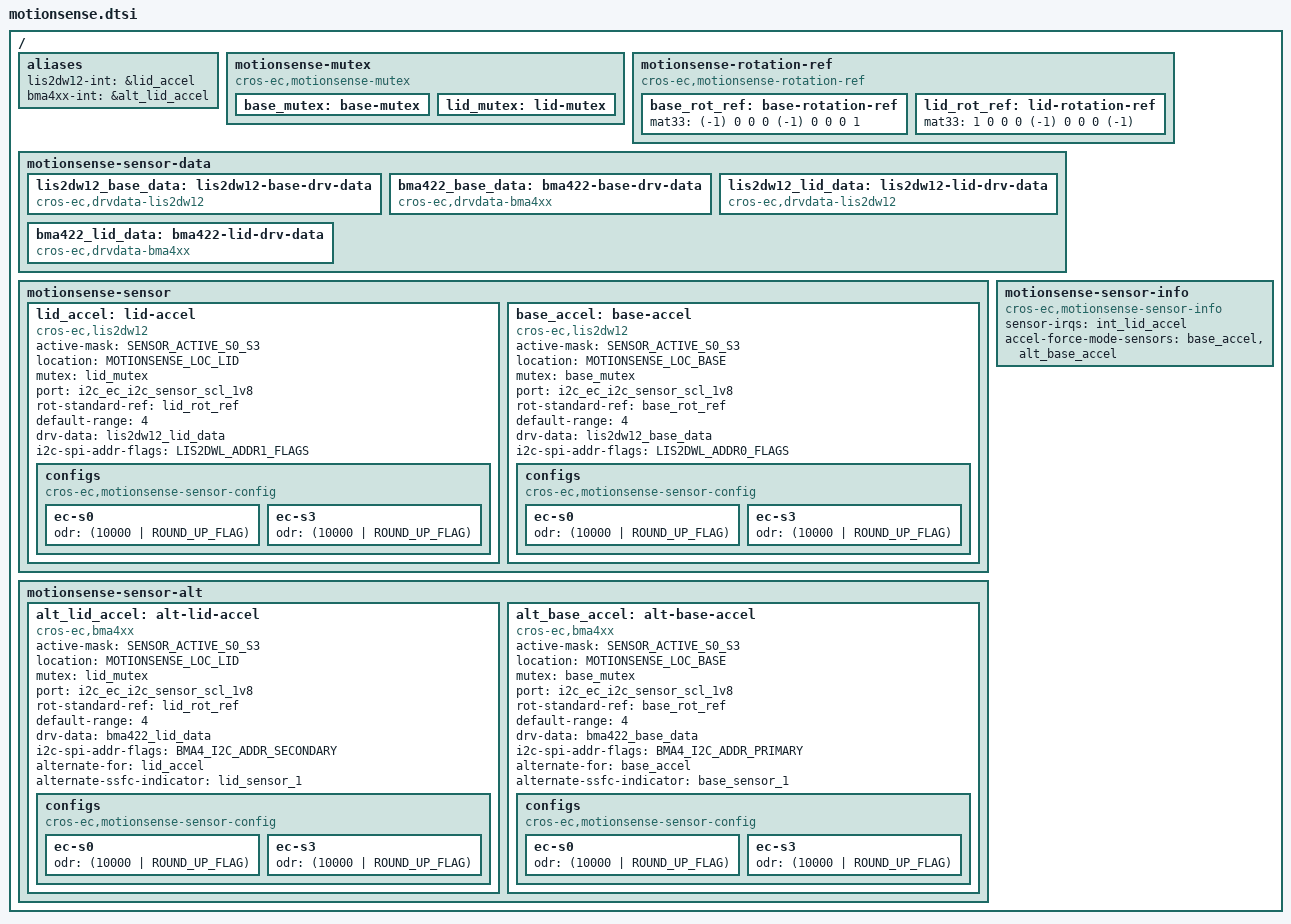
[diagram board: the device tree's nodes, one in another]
/* Copyright 2025 The ChromiumOS Authors
 * Use of this source code is governed by a BSD-style license that can be
 * found in the LICENSE file.
 */

 #include <dt-bindings/motionsense/utils.h>


/ {
	aliases {
		/*
		 * Interrupt bindings for sensor devices.
		 */
		lis2dw12-int = &lid_accel;
		bma4xx-int = &alt_lid_accel;
	};

	/*
	 * Declare mutexes used by sensor drivers.
	 * A mutex node is used to create an instance of mutex_t.
	 * A mutex node is referenced by a sensor node if the
	 * corresponding sensor driver needs to use the
	 * instance of the mutex.
	 */
	motionsense-mutex {
		compatible = "cros-ec,motionsense-mutex";

		base_mutex: base-mutex {
		};

		lid_mutex: lid-mutex {
		};
	};

	/* Rotation matrix used by drivers. */
	motionsense-rotation-ref {
		compatible = "cros-ec,motionsense-rotation-ref";

		base_rot_ref: base-rotation-ref {
			mat33 = <(-1) 0 0
				 0 (-1) 0
				 0 0 1>;
		};

		lid_rot_ref: lid-rotation-ref{
			mat33 = <1 0 0
				 0 (-1) 0
				 0 0 (-1)>;
		};	};

	/*
	 * Driver specific data. A driver-specific data can be shared with
	 * different motion sensors while they are using the same driver.
	 *
	 * If a node's compatible starts with "cros-ec,accelgyro-", it is for
	 * a common structure defined in accelgyro.h.
	 * e.g) compatible = "cros-ec,accelgyro-als-drv-data" is for
	 * "struct als_drv_data_t" in accelgyro.h
	 */
	motionsense-sensor-data {
		lis2dw12_base_data: lis2dw12-base-drv-data {
			compatible = "cros-ec,drvdata-lis2dw12";
			status = "okay";
		};
		bma422_base_data: bma422-base-drv-data {
			compatible = "cros-ec,drvdata-bma4xx";
			status = "okay";
		};
		lis2dw12_lid_data: lis2dw12-lid-drv-data {
			compatible = "cros-ec,drvdata-lis2dw12";
			status = "okay";
		};
		bma422_lid_data: bma422-lid-drv-data {
			compatible = "cros-ec,drvdata-bma4xx";
			status = "okay";
		};
	};

	/*
	 * List of motion sensors that creates motion_sensors array.
	 * The nodelabel "lid_accel" and "base_accel" are used to indicate
	 * motion sensor IDs for lid angle calculation.
	 * TODO(b/238139272): The first entries of the array must be
	 * accelerometers,then gyroscope. Fix this dependency in the DTS
	 * processing which makes the devicetree entries independent.
	 */
	motionsense-sensor {
		lid_accel: lid-accel {
			compatible = "cros-ec,lis2dw12";
			status = "okay";

			active-mask = "SENSOR_ACTIVE_S0_S3";
			location = "MOTIONSENSE_LOC_LID";
			mutex = <&lid_mutex>;
			port = <&i2c_ec_i2c_sensor_scl_1v8>;
			rot-standard-ref = <&lid_rot_ref>;
			default-range = <4>;
			drv-data = <&lis2dw12_lid_data>;
			i2c-spi-addr-flags = "LIS2DWL_ADDR1_FLAGS";
			configs {
				compatible =
					"cros-ec,motionsense-sensor-config";
				/* 50 Hz to support body detection. */
				ec-s0 {
					odr = <(10000 | ROUND_UP_FLAG)>;
				};
				ec-s3 {
					odr = <(10000 | ROUND_UP_FLAG)>;
				};
			};
		};

		base_accel: base-accel {
			compatible = "cros-ec,lis2dw12";
			status = "okay";

			active-mask = "SENSOR_ACTIVE_S0_S3";
			location = "MOTIONSENSE_LOC_BASE";
			mutex = <&base_mutex>;
			port = <&i2c_ec_i2c_sensor_scl_1v8>;
			rot-standard-ref = <&base_rot_ref>;
			default-range = <4>; /* to meet CDD 7.3.1/C-1-4 reqs. */
			drv-data = <&lis2dw12_base_data>;
			i2c-spi-addr-flags = "LIS2DWL_ADDR0_FLAGS";
			configs {
				compatible =
					"cros-ec,motionsense-sensor-config";
				/* 50 Hz to support body detection. */
				ec-s0 {
					odr = <(10000 | ROUND_UP_FLAG)>;
				};
				ec-s3 {
					odr = <(10000 | ROUND_UP_FLAG)>;
				};
			};
		};
	};
	motionsense-sensor-alt {
		alt_lid_accel: alt-lid-accel {
			compatible = "cros-ec,bma4xx";
			status = "okay";

			active-mask = "SENSOR_ACTIVE_S0_S3";
			location = "MOTIONSENSE_LOC_LID";
			mutex = <&lid_mutex>;
			port = <&i2c_ec_i2c_sensor_scl_1v8>;
			rot-standard-ref = <&lid_rot_ref>;
			default-range = <4>;
			drv-data = <&bma422_lid_data>;
			i2c-spi-addr-flags = "BMA4_I2C_ADDR_SECONDARY";
			alternate-for = <&lid_accel>;
			alternate-ssfc-indicator = <&lid_sensor_1>;
			configs {
				compatible =
					"cros-ec,motionsense-sensor-config";
				ec-s0 {
					odr = <(10000 | ROUND_UP_FLAG)>;
				};
				ec-s3 {
					odr = <(10000 | ROUND_UP_FLAG)>;
				};
			};
		};
		alt_base_accel: alt-base-accel {
			compatible = "cros-ec,bma4xx";
			status = "okay";

			active-mask = "SENSOR_ACTIVE_S0_S3";
			location = "MOTIONSENSE_LOC_BASE";
			mutex = <&base_mutex>;
			port = <&i2c_ec_i2c_sensor_scl_1v8>;
			rot-standard-ref = <&base_rot_ref>;
			default-range = <4>;
			drv-data = <&bma422_base_data>;
			i2c-spi-addr-flags = "BMA4_I2C_ADDR_PRIMARY";
			alternate-for = <&base_accel>;
			alternate-ssfc-indicator = <&base_sensor_1>;
			configs {
				compatible =
					"cros-ec,motionsense-sensor-config";
				ec-s0 {
					odr = <(10000 | ROUND_UP_FLAG)>;
				};
				ec-s3 {
					odr = <(10000 | ROUND_UP_FLAG)>;
				};
			};
		};
	};

	motionsense-sensor-info {
		compatible = "cros-ec,motionsense-sensor-info";

		sensor-irqs = <&int_lid_accel>;

		/* List of sensors in force mode */
		accel-force-mode-sensors = <&base_accel &alt_base_accel>;
	};
};
